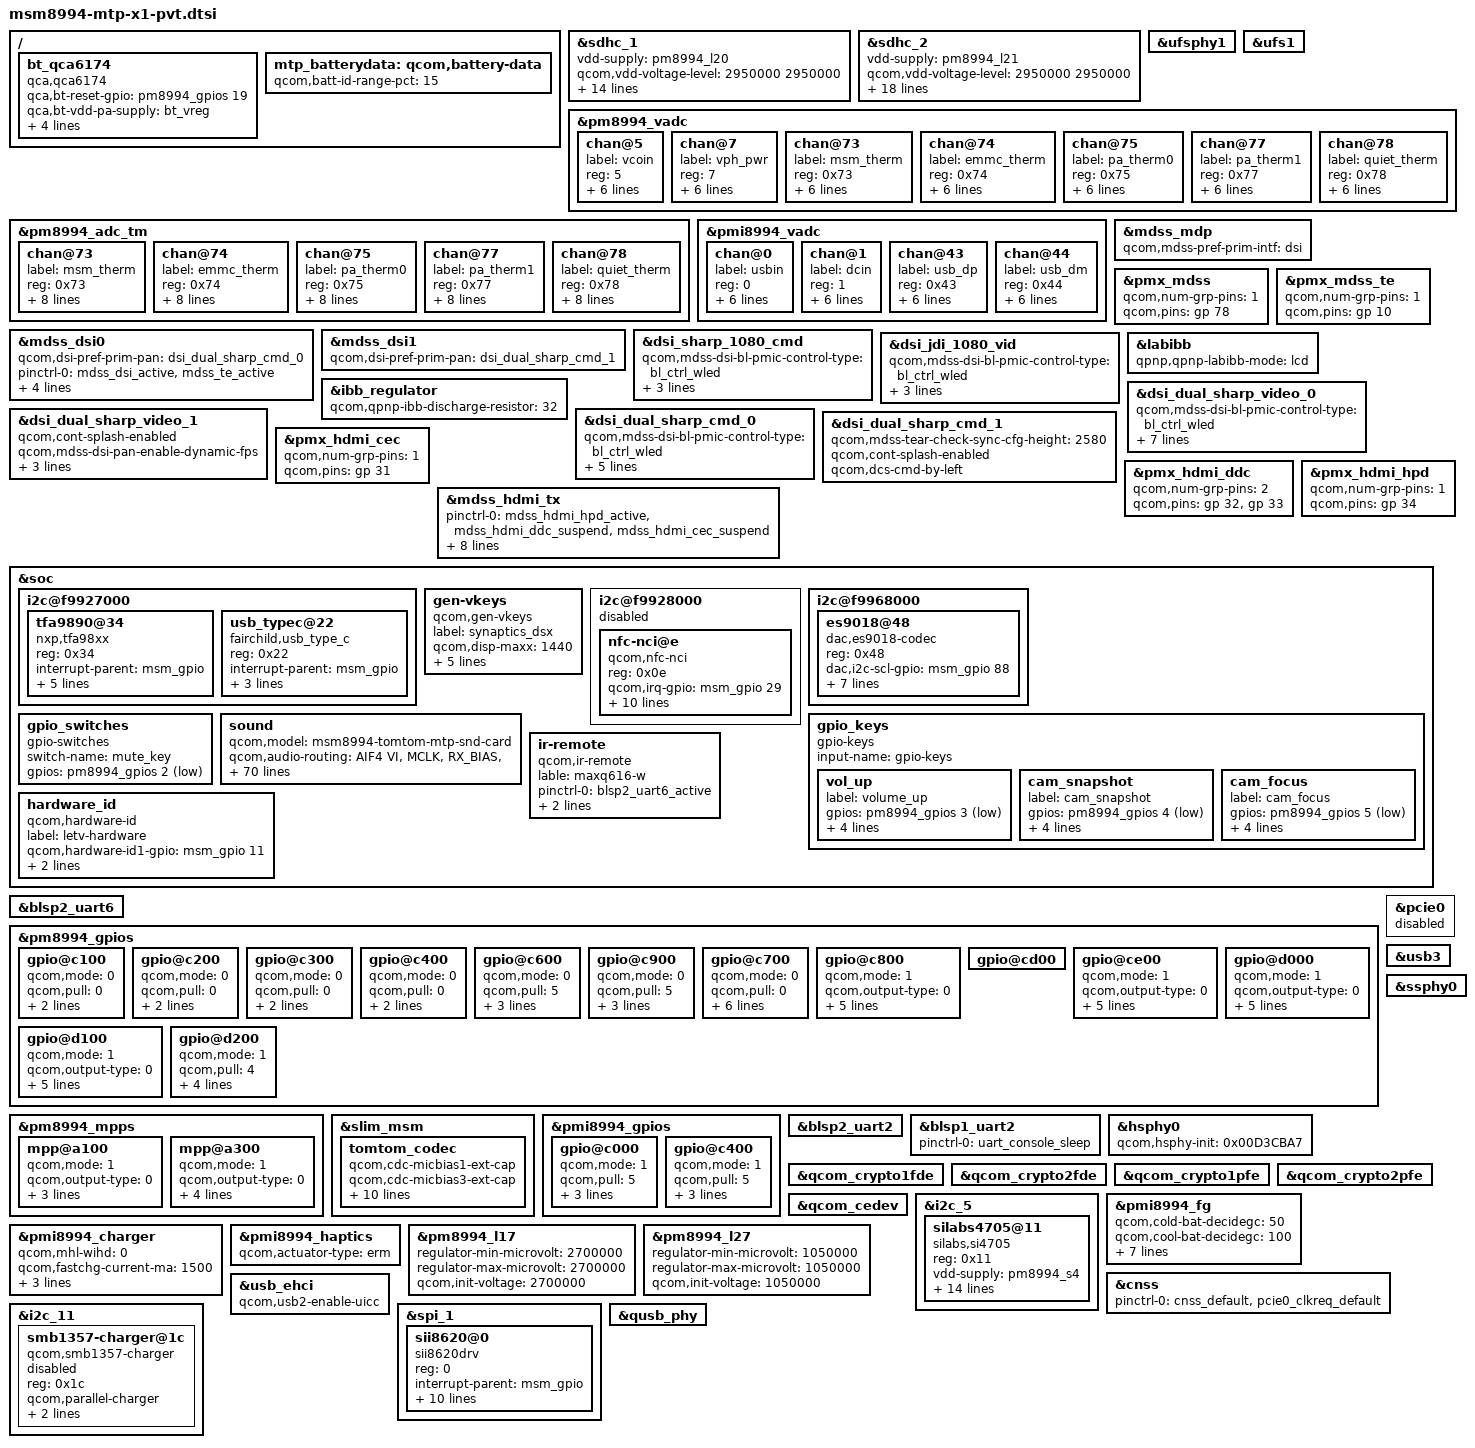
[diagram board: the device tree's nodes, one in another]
/* Copyright (c) 2014-2015, The Linux Foundation. All rights reserved.
 *
 * This program is free software; you can redistribute it and/or modify
 * it under the terms of the GNU General Public License version 2 and
 * only version 2 as published by the Free Software Foundation.
 *
 * This program is distributed in the hope that it will be useful,
 * but WITHOUT ANY WARRANTY; without even the implied warranty of
 * MERCHANTABILITY or FITNESS FOR A PARTICULAR PURPOSE.  See the
 * GNU General Public License for more details.
 */

#include "msm8994-pinctrl.dtsi"
#include "msm8994-camera-sensor-x1.dtsi"
#include "letv-msm8994-tp-x1-evt.dtsi"

/ {
	bt_qca6174 {
		compatible = "qca,qca6174";
		qca,bt-reset-gpio = <&pm8994_gpios 19 0>; /* BT_EN */
		qca,bt-vdd-pa-supply = <&bt_vreg>;
		qca,bt-vdd-io-supply = <&pm8994_s4>;
		qca,bt-vdd-xtal-supply = <&pm8994_l30>;
		qca,bt-vdd-io-voltage-level = <1800000 1800000>;
		qca,bt-vdd-xtal-voltage-level = <1800000 1800000>;
	};
};

&sdhc_1 {
	vdd-supply = <&pm8994_l20>;
	qcom,vdd-voltage-level = <2950000 2950000>;
	qcom,vdd-current-level = <200 570000>;

	vdd-io-supply = <&pm8994_s4>;
	qcom,vdd-io-always-on;
	qcom,vdd-io-voltage-level = <1800000 1800000>;
	qcom,vdd-io-current-level = <200 325000>;

	pinctrl-names = "active", "sleep";
	pinctrl-0 = <&sdc1_clk_on &sdc1_cmd_on &sdc1_data_on &sdc1_rclk_on>;
	pinctrl-1 = <&sdc1_clk_off &sdc1_cmd_off &sdc1_data_off &sdc1_rclk_off>;

	qcom,nonremovable;

	qcom,clk-rates = <400000 20000000 25000000 50000000 100000000 192000000 384000000>;
	qcom,bus-speed-mode = "HS400_1p8v", "HS200_1p8v", "DDR_1p8v";
	status = "ok";
};

&sdhc_2 {
	vdd-supply = <&pm8994_l21>;
	qcom,vdd-voltage-level = <2950000 2950000>;
	qcom,vdd-current-level = <200 800000>;

	vdd-io-supply = <&pm8994_l13>;
	qcom,vdd-io-voltage-level = <1800000 2950000>;
	qcom,vdd-io-current-level = <200 22000>;

	#address-cells = <0>;
	interrupt-parent = <&sdhc_2>;
	interrupts = <0 1 2>;
	#interrupt-cells = <1>;
	interrupt-map-mask = <0xffffffff>;
	interrupt-map = <0 &intc 0 125 0
			1 &intc 0 221 0
			2 &pm8994_gpios 8 0x3>;
	interrupt-names = "hc_irq", "pwr_irq", "status_irq";
	cd-gpios = <&pm8994_gpios 8 0x1>;

	pinctrl-names = "active", "sleep";
	pinctrl-0 = <&sdc2_clk_on &sdc2_cmd_on &sdc2_data_on>;
	pinctrl-1 = <&sdc2_clk_off &sdc2_cmd_off &sdc2_data_off>;

	qcom,clk-rates = <400000 20000000 25000000 50000000 100000000 200000000>;
	qcom,bus-speed-mode = "SDR12", "SDR25", "SDR50", "DDR50", "SDR104";
	status = "ok";
};

&ufsphy1 {
	status = "ok";
};

&ufs1 {
	status = "ok";
};

&pm8994_vadc {
	chan@5 {
		label = "vcoin";
		reg = <5>;
		qcom,decimation = <0>;
		qcom,pre-div-channel-scaling = <1>;
		qcom,calibration-type = "absolute";
		qcom,scale-function = <0>;
		qcom,hw-settle-time = <0>;
		qcom,fast-avg-setup = <0>;
	};

	chan@7 {
		label = "vph_pwr";
		reg = <7>;
		qcom,decimation = <0>;
		qcom,pre-div-channel-scaling = <1>;
		qcom,calibration-type = "absolute";
		qcom,scale-function = <0>;
		qcom,hw-settle-time = <0>;
		qcom,fast-avg-setup = <0>;
	};

	chan@73 {
		label = "msm_therm";
		reg = <0x73>;
		qcom,decimation = <0>;
		qcom,pre-div-channel-scaling = <0>;
		qcom,calibration-type = "ratiometric";
		qcom,scale-function = <2>;
		qcom,hw-settle-time = <2>;
		qcom,fast-avg-setup = <0>;
	};

	chan@74 {
		label = "emmc_therm";
		reg = <0x74>;
		qcom,decimation = <0>;
		qcom,pre-div-channel-scaling = <0>;
		qcom,calibration-type = "ratiometric";
		qcom,scale-function = <2>;
		qcom,hw-settle-time = <2>;
		qcom,fast-avg-setup = <0>;
	};

	chan@75 {
		label = "pa_therm0";
		reg = <0x75>;
		qcom,decimation = <0>;
		qcom,pre-div-channel-scaling = <0>;
		qcom,calibration-type = "ratiometric";
		qcom,scale-function = <2>;
		qcom,hw-settle-time = <2>;
		qcom,fast-avg-setup = <0>;
	};

	chan@77 {
		label = "pa_therm1";
		reg = <0x77>;
		qcom,decimation = <0>;
		qcom,pre-div-channel-scaling = <0>;
		qcom,calibration-type = "ratiometric";
		qcom,scale-function = <2>;
		qcom,hw-settle-time = <2>;
		qcom,fast-avg-setup = <0>;
	};

	chan@78 {
		label = "quiet_therm";
		reg = <0x78>;
		qcom,decimation = <0>;
		qcom,pre-div-channel-scaling = <0>;
		qcom,calibration-type = "ratiometric";
		qcom,scale-function = <2>;
		qcom,hw-settle-time = <2>;
		qcom,fast-avg-setup = <0>;
	};
};

&pm8994_adc_tm {
	chan@73 {
		label = "msm_therm";
		reg = <0x73>;
		qcom,decimation = <0>;
		qcom,pre-div-channel-scaling = <0>;
		qcom,calibration-type = "ratiometric";
		qcom,scale-function = <2>;
		qcom,hw-settle-time = <2>;
		qcom,fast-avg-setup = <0>;
		qcom,btm-channel-number = <0x48>;
		qcom,thermal-node;
	};

	chan@74 {
		label = "emmc_therm";
		reg = <0x74>;
		qcom,decimation = <0>;
		qcom,pre-div-channel-scaling = <0>;
		qcom,calibration-type = "ratiometric";
		qcom,scale-function = <2>;
		qcom,hw-settle-time = <2>;
		qcom,fast-avg-setup = <0>;
		qcom,btm-channel-number = <0x68>;
		qcom,thermal-node;
	};

	chan@75 {
		label = "pa_therm0";
		reg = <0x75>;
		qcom,decimation = <0>;
		qcom,pre-div-channel-scaling = <0>;
		qcom,calibration-type = "ratiometric";
		qcom,scale-function = <2>;
		qcom,hw-settle-time = <2>;
		qcom,fast-avg-setup = <0>;
		qcom,btm-channel-number = <0x70>;
		qcom,thermal-node;
	};

	chan@77 {
		label = "pa_therm1";
		reg = <0x77>;
		qcom,decimation = <0>;
		qcom,pre-div-channel-scaling = <0>;
		qcom,calibration-type = "ratiometric";
		qcom,scale-function = <2>;
		qcom,hw-settle-time = <2>;
		qcom,fast-avg-setup = <0>;
		qcom,btm-channel-number = <0x78>;
		qcom,thermal-node;
	};

	chan@78 {
		label = "quiet_therm";
		reg = <0x78>;
		qcom,decimation = <0>;
		qcom,pre-div-channel-scaling = <0>;
		qcom,calibration-type = "ratiometric";
		qcom,scale-function = <2>;
		qcom,hw-settle-time = <2>;
		qcom,fast-avg-setup = <0>;
		qcom,btm-channel-number = <0x80>;
		qcom,thermal-node;
	};
};

&pmi8994_vadc {
	chan@0 {
		label = "usbin";
		reg = <0>;
		qcom,decimation = <0>;
		qcom,pre-div-channel-scaling = <4>;
		qcom,calibration-type = "absolute";
		qcom,scale-function = <0>;
		qcom,hw-settle-time = <0>;
		qcom,fast-avg-setup = <0>;
	};

	chan@1 {
		label = "dcin";
		reg = <1>;
		qcom,decimation = <0>;
		qcom,pre-div-channel-scaling = <4>;
		qcom,calibration-type = "absolute";
		qcom,scale-function = <0>;
		qcom,hw-settle-time = <0>;
		qcom,fast-avg-setup = <0>;
	};

	chan@43 {
		label = "usb_dp";
		reg = <0x43>;
		qcom,decimation = <0>;
		qcom,pre-div-channel-scaling = <1>;
		qcom,calibration-type = "absolute";
		qcom,scale-function = <0>;
		qcom,hw-settle-time = <0>;
		qcom,fast-avg-setup = <0>;
	};

	chan@44 {
		label = "usb_dm";
		reg = <0x44>;
		qcom,decimation = <0>;
		qcom,pre-div-channel-scaling = <1>;
		qcom,calibration-type = "absolute";
		qcom,scale-function = <0>;
		qcom,hw-settle-time = <0>;
		qcom,fast-avg-setup = <0>;
	};
};

/*#include "dsi-panel-sharp-dualmipi0-wqxga-video.dtsi" */
/*#include "dsi-panel-sharp-dualmipi1-wqxga-video.dtsi" */

#include "dsi-panel-jdi-1080p-video.dtsi"
#include "dsi-panel-sharp-1080p-cmd.dtsi"

#include "dsi-panel-sharp-x1-dualmipi0-cmd.dtsi"
#include "dsi-panel-sharp-x1-dualmipi1-cmd.dtsi"
#include "dsi-panel-sharp-dualmipi0-video.dtsi"
#include "dsi-panel-sharp-dualmipi1-video.dtsi"

&mdss_mdp {
	qcom,mdss-pref-prim-intf = "dsi";
};

&pmx_mdss {
	qcom,num-grp-pins = <1>;
	qcom,pins = <&gp 78>;
};

&pmx_mdss_te {
	qcom,num-grp-pins = <1>;
	qcom,pins = <&gp 10>;
};

&mdss_dsi0 {
	qcom,dsi-pref-prim-pan = <&dsi_dual_sharp_cmd_0>;
	pinctrl-names = "mdss_default", "mdss_sleep";
	pinctrl-0 = <&mdss_dsi_active &mdss_te_active>;
	pinctrl-1 = <&mdss_dsi_suspend &mdss_te_suspend>;

	qcom,dsi-panel-bias-vreg;
	qcom,platform-reset-gpio = <&msm_gpio 78 0>;
	qcom,platform-te-gpio = <&msm_gpio 10 0>;
	/delete-property/ qcom,platform-bklight-en-gpio;
	/delete-property/ qcom,platform-enable-gpio;
};

&mdss_dsi1 {
	qcom,dsi-pref-prim-pan = <&dsi_dual_sharp_cmd_1>;
};

&dsi_sharp_1080_cmd {
	qcom,mdss-dsi-bl-pmic-control-type = "bl_ctrl_wled";
	qcom,mdss-dsi-bl-min-level = <1>;
	qcom,mdss-dsi-bl-max-level = <4095>;
	qcom,cont-splash-enabled;
};

&dsi_jdi_1080_vid {
	qcom,mdss-dsi-bl-pmic-control-type = "bl_ctrl_wled";
	qcom,mdss-dsi-bl-min-level = <1>;
	qcom,mdss-dsi-bl-max-level = <4095>;
	qcom,cont-splash-enabled;
};

&labibb {
	status = "ok";
	qpnp,qpnp-labibb-mode = "lcd";
};

&ibb_regulator {
	qcom,qpnp-ibb-discharge-resistor = <32>;
};

&dsi_dual_sharp_video_0 {
	qcom,mdss-dsi-bl-pmic-control-type = "bl_ctrl_wled";
	qcom,mdss-dsi-bl-min-level = <1>;
	qcom,mdss-dsi-bl-max-level = <4095>;
	qcom,cont-splash-enabled;
	qcom,mdss-dsi-pan-enable-dynamic-fps;
	qcom,mdss-dsi-pan-fps-update = "dfps_immediate_porch_mode_vfp";
	qcom,mdss-dsi-min-refresh-rate = <30>;
};

&dsi_dual_sharp_video_1 {
	qcom,cont-splash-enabled;
	qcom,mdss-dsi-pan-enable-dynamic-fps;
	qcom,mdss-dsi-pan-fps-update = "dfps_immediate_porch_mode_vfp";
	qcom,mdss-dsi-min-refresh-rate = <30>;
};

/* add sharp panel cmd mode */
&dsi_dual_sharp_cmd_0 {
	qcom,mdss-dsi-bl-pmic-control-type = "bl_ctrl_wled";
	qcom,mdss-dsi-bl-min-level = <1>;
	qcom,mdss-dsi-bl-max-level = <4095>;
	qcom,mdss-tear-check-sync-cfg-height = <2580>; 
	qcom,cont-splash-enabled;
	qcom,dcs-cmd-by-left;
};

&dsi_dual_sharp_cmd_1 {
	qcom,mdss-tear-check-sync-cfg-height = <2580>; 
	qcom,cont-splash-enabled;
	qcom,dcs-cmd-by-left;
};

&pmx_hdmi_cec {
	qcom,num-grp-pins = <1>;
	qcom,pins = <&gp 31>;
};

&pmx_hdmi_ddc {
	qcom,num-grp-pins = <2>;
	qcom,pins = <&gp 32>, <&gp 33>;
};

&pmx_hdmi_hpd {
	qcom,num-grp-pins = <1>;
	qcom,pins = <&gp 34>;
};

&mdss_hdmi_tx {
	pinctrl-names = "hdmi_hpd_active", "hdmi_ddc_active",
				"hdmi_cec_active", "hdmi_active",
				"hdmi_sleep";
	pinctrl-0 = <&mdss_hdmi_hpd_active &mdss_hdmi_ddc_suspend
						&mdss_hdmi_cec_suspend>;
	pinctrl-1 = <&mdss_hdmi_hpd_active &mdss_hdmi_ddc_active
						&mdss_hdmi_cec_suspend>;
	pinctrl-2 = <&mdss_hdmi_hpd_active &mdss_hdmi_cec_active
						&mdss_hdmi_ddc_suspend>;
	pinctrl-3 = <&mdss_hdmi_hpd_active &mdss_hdmi_ddc_active
						&mdss_hdmi_cec_active>;
	pinctrl-4 = <&mdss_hdmi_hpd_suspend &mdss_hdmi_ddc_suspend
						&mdss_hdmi_cec_suspend>;
};

&soc {
	i2c@f9927000 { /* BLSP1 QUP5 */
		status = "ok";
		tfa9890@34 {
			compatible = "nxp,tfa98xx";
			reg = <0x34>;
			interrupt-parent = <&msm_gpio>;
			interrupts = <1 0x2>;
			irq-gpio = <&msm_gpio 1 0x00>;
			nxp,rst-ctrl-gpio = <&msm_gpio 0 0x00>;
			tfa9890,i2c-pull-up;
			tfa9890,power-down;
		};
		usb_typec@22 {
			compatible = "fairchild,usb_type_c";
			reg = <0x22>;
			interrupt-parent = <&msm_gpio>;
			interrupts = <108 0x02>;
			irq-gpio = <&msm_gpio 108 0x00>;
			pinctrl-names = "fusb300_active";
			pinctrl-0 = <&fusb_active>;
		};
	};

	gen-vkeys {
		compatible = "qcom,gen-vkeys";
		label = "synaptics_dsx";
		/*qcom,disp-maxx = <1599>;
		qcom,disp-maxy = <2559>;
		qcom,panel-maxx = <1599>;
		qcom,panel-maxy = <2703>;
		qcom,key-codes = <158 139 102 217>;*/
		qcom,disp-maxx = <1440>;
		qcom,disp-maxy = <2560>;
		qcom,panel-maxx = <1440>;
		qcom,panel-maxy = <2775>;
		qcom,key-codes = <580 102 158>;
                qcom,y-offset = <30>;
	};

	i2c@f9928000 { /* BLSP1 QUP6 */
		status = "disabled";
		nfc-nci@e {
			compatible = "qcom,nfc-nci";
			reg = <0x0e>;
			qcom,irq-gpio = <&msm_gpio 29 0x00>;
			qcom,dis-gpio = <&msm_gpio 30 0x00>;
			qcom,clk-src = "BBCLK2";
			interrupt-parent = <&msm_gpio>;
			interrupts = <29 0>;
			interrupt-names = "nfc_irq";
			pinctrl-names = "nfc_active","nfc_suspend";
			pinctrl-0 = <&nfc_int_active &nfc_disable_active>;
			pinctrl-1 = <&nfc_int_suspend &nfc_disable_suspend>;
			qcom,clk-gpio = <&pm8994_gpios 10 0>;
			qcom,pwr-req-gpio = <&pm8994_gpios 7 0>;
			clocks = <&clock_rpm clk_bb_clk2_pin>;
			clock-names = "ref_clk";
		};
	};

	i2c@f9968000 { /* BLSP1 QUP5 */
		status = "ok";
		es9018@48 {
			compatible = "dac,es9018-codec";
			reg = <0x48>;
			dac,i2c-scl-gpio = <&msm_gpio 88 0x00>;
			dac,i2c-sda-gpio = <&msm_gpio 87 0x00>;
			es9018,reset-gpio = <&msm_gpio 74 0x00>;
			es9018,clk_gpio_45M = <&msm_gpio 40 0x00>;
			es9018,clk_gpio_49M = <&msm_gpio 41 0x00>;
			es9018,ldo_ena_92 = <&msm_gpio 92 0x00>;
			es9018,ldo_ena_96 = <&msm_gpio 96 0x00>;
			es9018,bypass_ctl_89 = <&msm_gpio 89 0x00>;
		};
	};

	gpio_keys {
		compatible = "gpio-keys";
		input-name = "gpio-keys";

		vol_up {
			label = "volume_up";
			gpios = <&pm8994_gpios 3 0x1>;
			linux,input-type = <1>;
			linux,code = <115>;
			gpio-key,wakeup;
			debounce-interval = <15>;
		};

		cam_snapshot {
			label = "cam_snapshot";
			gpios = <&pm8994_gpios 4 0x1>;
			linux,input-type = <1>;
			linux,code = <766>;
			gpio-key,wakeup;
			debounce-interval = <15>;
		};

		cam_focus {
			label = "cam_focus";
			gpios = <&pm8994_gpios 5 0x1>;
			linux,input-type = <1>;
			linux,code = <528>;
			gpio-key,wakeup;
			debounce-interval = <15>;
		};


	};


        gpio_switches{
		compatible = "gpio-switches";
		switch-name = "mute_key";
		gpios = <&pm8994_gpios 2 0x1>;
	};

	sound {
		qcom,model = "msm8994-tomtom-mtp-snd-card";

		qcom,audio-routing =
			"AIF4 VI", "MCLK",
			"RX_BIAS", "MCLK",
			"LDO_H", "MCLK",
			"MADINPUT", "MCLK",
			"ultrasound amp", "LINEOUT1",
			"ultrasound amp", "LINEOUT3",
			/*"AMIC1", "MIC BIAS1 Internal1",
			"MIC BIAS1 Internal1", "Handset Mic",*/
			"AMIC1", "MIC BIAS1 External",
			"MIC BIAS1 External", "Handset Mic",
			"AMIC2", "MIC BIAS2 External",
			"MIC BIAS2 External", "Headset Mic",
			"AMIC3", "MIC BIAS2 External",
			"MIC BIAS2 External", "ANCRight Headset Mic",
			/*"AMIC4", "MIC BIAS2 External",
			"MIC BIAS2 External", "ANCLeft Headset Mic",*/
			"AMIC4", "MIC BIAS4 External",
			"MIC BIAS4 External", "ANCLeft Headset Mic",
			"AMIC5", "MIC BIAS3 External",
			"MIC BIAS3 External", "Analog Mic5",
			"AMIC6", "MIC BIAS4 External",
			"MIC BIAS4 External", "Analog Mic6",
			"DMIC1", "MIC BIAS1 External",
			"MIC BIAS1 External", "Digital Mic1",
			"DMIC2", "MIC BIAS1 External",
			"MIC BIAS1 External", "Digital Mic2",
			"DMIC3", "MIC BIAS3 External",
			"MIC BIAS3 External", "Digital Mic3",
			"DMIC4", "MIC BIAS3 External",
			"MIC BIAS3 External", "Digital Mic4",
			"DMIC5", "MIC BIAS4 External",
			"MIC BIAS4 External", "Digital Mic5",
			"DMIC6", "MIC BIAS4 External",
			"MIC BIAS4 External", "Digital Mic6";
		pinctrl-names = "pri_auxpcm_quat_sleep",
				"pri_active_auxpcm_quat_sleep",
				"pri_quat_sleep_auxpcm_active",
				"pri_auxpcm_sleep_quat_active",
				"pri_auxpcm_active_quat_sleep",
				"pri_quat_active_auxpcm_sleep",
				"pri_sleep_auxpcm_quat_active",
				"pri_auxpcm_quat_active";
		pinctrl-0 = <&pri_mi2s_sleep>, <&pri_mi2s_sd0_sleep>, <&pri_mi2s_sd1_sleep>,
				<&sec_aux_pcm_sleep>, <&sec_aux_pcm_din_sleep>,
				<&quat_mi2s_sleep>, <&quat_mi2s_mclk_2_sleep>, <&quat_mi2s_sd0_2_sleep>;
		pinctrl-1 = <&pri_mi2s_active>, <&pri_mi2s_sd0_active>, <&pri_mi2s_sd1_active>,
				<&sec_aux_pcm_sleep>, <&sec_aux_pcm_din_sleep>,
				<&quat_mi2s_sleep>, <&quat_mi2s_mclk_2_sleep>, <&quat_mi2s_sd0_2_sleep>;
		pinctrl-2 = <&pri_mi2s_sleep>, <&pri_mi2s_sd0_sleep>, <&pri_mi2s_sd1_sleep>,
				<&sec_aux_pcm_active>, <&sec_aux_pcm_din_active>,
				<&quat_mi2s_sleep>, <&quat_mi2s_mclk_2_sleep>, <&quat_mi2s_sd0_2_sleep>;
		pinctrl-3 = <&pri_mi2s_sleep>, <&pri_mi2s_sd0_sleep>, <&pri_mi2s_sd1_sleep>,
				<&sec_aux_pcm_sleep>, <&sec_aux_pcm_din_sleep>,
				<&quat_mi2s_2_active>, <&quat_mi2s_mclk_2_active>, <&quat_mi2s_sd0_2_active>;
		pinctrl-4 = <&pri_mi2s_active>, <&pri_mi2s_sd0_active>, <&pri_mi2s_sd1_active>,
				<&sec_aux_pcm_active>, <&sec_aux_pcm_din_active>,
				<&quat_mi2s_sleep>, <&quat_mi2s_mclk_2_sleep>, <&quat_mi2s_sd0_2_sleep>;
		pinctrl-5 = <&pri_mi2s_active>, <&pri_mi2s_sd0_active>, <&pri_mi2s_sd1_active>,
				<&sec_aux_pcm_sleep>, <&sec_aux_pcm_din_sleep>,
				<&quat_mi2s_2_active>, <&quat_mi2s_mclk_2_active>, <&quat_mi2s_sd0_2_active>;
		pinctrl-6 = <&pri_mi2s_sleep>, <&pri_mi2s_sd0_sleep>, <&pri_mi2s_sd1_sleep>,
				<&sec_aux_pcm_active>, <&sec_aux_pcm_din_active>,
				<&quat_mi2s_2_active>, <&quat_mi2s_mclk_2_active>, <&quat_mi2s_sd0_2_active>;
		pinctrl-7 = <&pri_mi2s_active>, <&pri_mi2s_sd0_active>, <&pri_mi2s_sd1_active>,
				<&sec_aux_pcm_active>, <&sec_aux_pcm_din_active>,
				<&quat_mi2s_2_active>, <&quat_mi2s_mclk_2_active>, <&quat_mi2s_sd0_2_active>;
		/* qcom,us-euro-gpios = <&pm8994_mpps 2 0>; */
		qcom,cdc-micbias2-headset-only;
		/* qcom,mbhc-audio-jack-type = "6-pole-jack"; */
		qcom,mbhc-audio-jack-type = "4-pole-jack";
		qcom,ext-ult-spk-amp-gpio = <&pmi8994_gpios 1 0>;
		qcom,hdmi-audio-rx;
		asoc-codec = <&stub_codec>, <&hdmi_audio>;
		asoc-codec-names = "msm-stub-codec.1", "msm-hdmi-audio-codec-rx";
		hardware-version = <2>;
	};

	ir-remote {
		compatible = "qcom,ir-remote";
		lable = "maxq616-w";
		pinctrl-names = "default", "sleep";
		pinctrl-0 = <&blsp2_uart6_active>;
		pinctrl-1 = <&blsp2_uart6_sleep>;
		qcom,ir-en-gpio = <&msm_gpio 90 0>;
	};

	hardware_id {
		compatible = "qcom,hardware-id";
		label = "letv-hardware";
		qcom,hardware-id1-gpio = <&msm_gpio 11 0>;
		qcom,hardware-id2-gpio = <&msm_gpio 12 0>;
		qcom,hardware-id3-gpio = <&msm_gpio 16 0>;
	};
};

&blsp2_uart6 {
	status = "ok";
};

&pm8994_gpios {
	gpio@c100 { /* GPIO 2 */
		qcom,mode = <0>;
		qcom,pull = <0>;
		qcom,vin-sel = <2>;
		qcom,src-sel = <0>;
		status = "okay";
	};

	gpio@c200 { /* GPIO 3 */
		qcom,mode = <0>;
		qcom,pull = <0>;
		qcom,vin-sel = <2>;
		qcom,src-sel = <0>;
		status = "okay";
	};
	gpio@c300 { /* GPIO 4 */
		qcom,mode = <0>;
		qcom,pull = <0>;
		qcom,vin-sel = <2>;
		qcom,src-sel = <0>;
		status = "okay";
	};

	gpio@c400 { /* GPIO 5 */
		qcom,mode = <0>;
		qcom,pull = <0>;
		qcom,vin-sel = <2>;
		qcom,src-sel = <0>;
		status = "okay";
	};

	gpio@c600 { /* GPIO 7 */
		/* NFC pwr request */
		qcom,mode = <0>;                /* QPNP_PIN_MODE_DIG_IN */
		qcom,pull = <5>;                /* QPNP_PIN_PULL_NO */
		qcom,vin-sel = <2>;             /* QPNP_PIN_VIN2 */
		qcom,src-sel = <2>;             /* QPNP_PIN_SEL_FUNC_1 */
		qcom,master-en = <1>;
		status = "okay";
	};

	gpio@c900 { /* GPIO 10 */
		/* NFC clk request */
		qcom,mode = <0>;                /* QPNP_PIN_MODE_DIG_IN */
		qcom,pull = <5>;                /* QPNP_PIN_PULL_NO */
		qcom,vin-sel = <2>;             /* QPNP_PIN_VIN2 */
		qcom,src-sel = <2>;             /* QPNP_PIN_SEL_FUNC_1 */
		qcom,master-en = <1>;
		status = "okay";
	};

	gpio@c700 { /* GPIO 8 */
		qcom,mode = <0>;                /* Digital in */
		qcom,pull = <0>;                /* PULL up 30uA */
		qcom,output-type = <0>;         /* CMOS logic */
		qcom,invert = <0>;              /* Output high */
		qcom,vin-sel = <2>;             /* Logical 1 voltage value 1.8v */
		qcom,src-sel = <0>;             /* Constant */
		qcom,out-strength = <1>;        /* Low drive strength */
		qcom,master-en = <1>;           /* Enable GPIO */
		status = "okay";
	};

	gpio@c800 { /* GPIO 9 */
		qcom,mode = <1>;		/* Digital output */
		qcom,output-type = <0>;		/* CMOS logic */
		qcom,invert = <1>;		/* Output high */
		qcom,vin-sel = <0>;		/* VPH_PWR */
		qcom,src-sel = <0>;		/* Constant */
		qcom,out-strength = <1>;	/* High drive strength */
		qcom,master-en = <1>;		/* Enable GPIO */
		status = "okay";
	};

	gpio@cd00 { /* GPIO 14 */
		status = "okay";
	};

	gpio@ce00 { /* GPIO 15 */
		qcom,mode = <1>;
		qcom,output-type = <0>;
		qcom,pull = <5>;
		qcom,vin-sel = <2>;
		qcom,out-strength = <1>;
		qcom,src-sel = <2>;
		qcom,master-en = <1>;
		status = "okay";
	};

	gpio@d000 { /* GPIO 17 */
                /* DIVCLK3 */
		qcom,mode = <1>;		/* Digital output */
		qcom,output-type = <0>;		/* CMOS logic */
		qcom,invert = <0>;		/* Output low initially */
		qcom,vin-sel = <2>;		/* VIN 2 */
		qcom,src-sel = <2>;		/* SPECIAL_FUNCTION1 */
		qcom,out-strength = <2>;	/* Medium */
		qcom,master-en = <1>;		/* Enable GPIO */
		status = "okay";
	};

	gpio@d100 { /* GPIO 18 */
		qcom,mode = <1>;		/* Digital output */
		qcom,output-type = <0>;		/* CMOS logic */
		qcom,invert = <0>;		/* Output low initially */
		qcom,vin-sel = <2>;		/* VIN 2 */
		qcom,src-sel = <3>;		/* Function 2 */
		qcom,out-strength = <2>;	/* Medium */
		qcom,master-en = <1>;		/* Enable GPIO */
		status = "okay";
	};

	gpio@d200 { /* GPIO 19 */
		qcom,mode = <1>;         /* Digital output*/
		qcom,pull = <4>;         /* Pulldown 10uA */
		qcom,vin-sel = <2>;      /* VIN2 */
		qcom,src-sel = <0>;      /* GPIO */
		qcom,invert = <0>;       /* Invert */
		qcom,master-en = <1>;    /* Enable GPIO */
		status = "okay";
	};
};

&pm8994_mpps {
	mpp@a100 { /* MPP 2 */
		qcom,mode = <1>;		/* Digital output */
		qcom,output-type = <0>;		/* CMOS logic */
		qcom,vin-sel = <2>;		/* S4 1.8V */
		qcom,src-sel = <0>;		/* Constant */
		qcom,master-en = <1>;		/* Enable GPIO */
		status = "okay";
	};

	mpp@a300 { /* MPP 4 */
		/* HDMI_5v_vreg regulator enable */
		qcom,mode = <1>;		/* Digital output */
		qcom,output-type = <0>;		/* CMOS logic */
		qcom,vin-sel = <2>;		/* S4 1.8V */
		qcom,src-sel = <0>;		/* Constant */
		qcom,master-en = <1>;		/* Enable GPIO */
		qcom,invert = <0>;
		status = "okay";
	};
};

&slim_msm {
	tomtom_codec {
		qcom,cdc-micbias1-ext-cap;
		qcom,cdc-micbias3-ext-cap;
		qcom,cdc-micbias4-ext-cap;
		cdc-vdd-spkdrv-supply = <&pmi8994_boost_pin_ctrl>;
		qcom,cdc-vdd-spkdrv-voltage = <5000000 5000000>;
		qcom,cdc-vdd-spkdrv-current = <600000>;

		cdc-vdd-spkdrv-2-supply = <&pmi8994_boost_pin_ctrl>;
		qcom,cdc-vdd-spkdrv-2-voltage = <5000000 5000000>;
		qcom,cdc-vdd-spkdrv-2-current = <600000>;

		qcom,cdc-on-demand-supplies = "cdc-vdd-spkdrv",
					      "cdc-vdd-spkdrv-2";
	};
};

&pmi8994_gpios {
	gpio@c000 {	/* GPIO 1  Ultrasound PA EN */
		qcom,mode = <1>;	/* DIGITAL OUT */
		qcom,pull = <5>;	/* No Pull */
		qcom,vin-sel = <2>;	/* 1.8 */
		qcom,src-sel = <0>;	/* CONSTANT */
		qcom,master-en = <1>;	/* ENABLE GPIO */
		status = "okay";
	};

	gpio@c400 {	/* GPIO 5  OTG SWITCH EN */
		qcom,mode = <1>;	/* DIGITAL OUT */
		qcom,pull = <5>;	/* No Pull */
		qcom,vin-sel = <2>;	/* 1.8 */
		qcom,src-sel = <0>;	/* GPIO */
		qcom,master-en = <1>;	/* ENABLE GPIO */
		status = "okay";
	};
};

#if 0
&pmi8994_mpps {
	mpp@a300 { /* MPP 4 */
		/* WLED FET */
		qcom,mode = <1>;	/* DIGITAL OUT */
		qcom,vin-sel = <0>;	/* VIN0 */
		qcom,master-en = <1>;
		status = "okay";
	};
};
#endif

&blsp2_uart2 {
	status = "ok";
};

&blsp1_uart2 {
	status= "ok";
	 pinctrl-names = "default";
	 pinctrl-0 = <&uart_console_sleep>;
};

&pcie0 {
	status = "disabled";
};

&usb3 {
	status = "ok";
};

&hsphy0 {
	status = "ok";
	qcom,hsphy-init = <0x00D3CBA7>;
};

&ssphy0 {
	status = "ok";
};

&qcom_crypto1fde {
	status = "okay";
};

&qcom_crypto2fde {
	status = "okay";
};

&qcom_crypto1pfe {
	status = "okay";
};

&qcom_crypto2pfe {
	status = "okay";
};

&qcom_cedev {
	status = "okay";
};

&i2c_5 {
	silabs4705@11 { /* SiLabs FM chip, slave id 0x11*/
		status = "ok";
		compatible = "silabs,si4705";
		reg = <0x11>;
		vdd-supply = <&pm8994_s4>;
		silabs,vdd-supply-voltage = <1800000 1800000>;
		va-supply = <&bt_vreg>;
		silabs,va-supply-voltage = <3300000 3300000>;
		pinctrl-names = "pmx_fm_active","pmx_fm_suspend";
		pinctrl-0 = <&fm_int_active &fm_status_int_active &fm_rst_active>;
		pinctrl-1 = <&fm_int_suspend &fm_status_int_suspend &fm_rst_suspend>;
		silabs,reset-gpio = <&msm_gpio 62 0>;
		silabs,int-gpio = <&msm_gpio 9 0>;
		silabs,status-gpio = <&msm_gpio 11 0>;
		#address-cells = <0>;
		interrupts = <0 1>;
		#interrupt-cells = <1>;
		interrupt-map-mask = <0xffffffff>;
		interrupt-map = <
				  0 &msm_gpio 9 2
				  1 &msm_gpio 11 1
				>;
		interrupt-names = "silabs_fm_int", "silabs_fm_status_int";
	};
};

/{
	mtp_batterydata: qcom,battery-data {
		qcom,batt-id-range-pct = <15>;
		#include "batterydata-x1-3000mah.dtsi"
	};
};

&pmi8994_fg {
	qcom,cold-bat-decidegc = <50>;
	qcom,cool-bat-decidegc = <100>;
	qcom,warm-bat-decidegc = <450>;
	qcom,hot-bat-decidegc = <550>;
	qcom,fg-iterm-ma = <250>;
	qcom,fg-chg-iterm-ma = <100>;
	qcom,fg-cc-cv-threshold-mv = <4340>;
	qcom,vbat-estimate-diff-mv = <100>;
	qcom,thermal-coefficients = [1D 86 13 4B 15 36];
};

&pmi8994_charger {
	qcom,mhl-wihd = <0>;
	qcom,fastchg-current-ma = <1500>;
	qcom,fastchg-current-comp = <900>;
	qcom,float-voltage-comp = <13>;
	qcom,iterm-ma = <100>;
};

&pmi8994_haptics {
	status = "okay";
        qcom,actuator-type = "erm";
};

&pm8994_l17{
	regulator-min-microvolt = <2700000>;
	regulator-max-microvolt = <2700000>;
	qcom,init-voltage = <2700000>;
};

&pm8994_l27{
	regulator-min-microvolt = <1050000>;
	regulator-max-microvolt = <1050000>;
	qcom,init-voltage = <1050000>;
};

&cnss {
	pinctrl-names = "default";
	pinctrl-0 = <&cnss_default &pcie0_clkreq_default>;
};

&i2c_11 {
	smb1357-charger@1c {
		compatible = "qcom,smb1357-charger";
		reg = <0x1c>;
		qcom,parallel-charger;
		qcom,float-voltage-mv = <4400>;
		qcom,recharge-thresh-mv = <100>;
		status = "disabled";
	};
};

&usb_ehci {
	status = "ok";
	qcom,usb2-enable-uicc;
};

/* SiI8620 device for MHL/WiHD function */
&spi_1 {
	status = "ok";
	sii8620@0 {
		compatible = "sii8620drv";
		reg = <0>;
		interrupt-parent = <&msm_gpio>;
		interrupts = <76 0>;
		spi-max-frequency = <19200000>;
		intr-gpio = <&msm_gpio 76 0>;
		rst-gpio = <&msm_gpio 39 0>;
		wakeup-gpio = <&msm_gpio 94 0>;
		mhl-sel1-gpio = <&msm_gpio 102 0>;
		vdd-mhl-supply = <&pm8994_l25>;
		mhl-clk-gpio = <&pm8994_gpios 17 0>;
		clocks = <&clock_rpm clk_div_clk3>;
		clock-names = "mhl_clk";

		qcom,hdmi-tx-map = <&mdss_hdmi_tx>;
	};
};

&qusb_phy {
	status = "ok";
};
